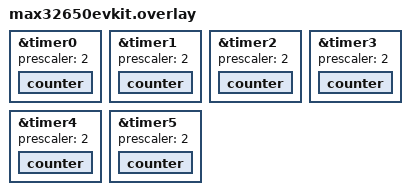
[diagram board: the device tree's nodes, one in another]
/*
 * Copyright (c) 2025 Analog Devices, Inc.
 *
 * SPDX-License-Identifier: Apache-2.0
 */

&timer0 {
	prescaler = <2>;
	status = "okay";

	counter {
		status = "okay";
	};
};

&timer1 {
	prescaler = <2>;
	status = "okay";

	counter {
		status = "okay";
	};
};

&timer2 {
	prescaler = <2>;
	status = "okay";

	counter {
		status = "okay";
	};
};

&timer3 {
	prescaler = <2>;
	status = "okay";

	counter {
		status = "okay";
	};
};

&timer4 {
	prescaler = <2>;
	status = "okay";

	counter {
		status = "okay";
	};
};

&timer5 {
	prescaler = <2>;
	status = "okay";

	counter {
		status = "okay";
	};
};
